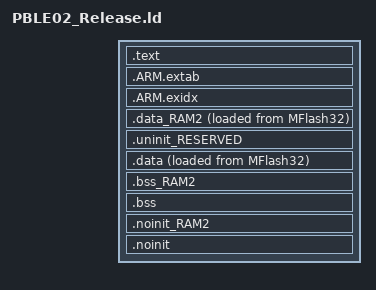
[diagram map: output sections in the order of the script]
/*
 * GENERATED FILE - DO NOT EDIT
 * Copyright 2008-2013 Code Red Technologies Ltd,
 * Copyright 2013-2025 NXP
 * SPDX-License-Identifier: BSD-3-Clause
 * Generated linker script file for LPC11U14/201
 * Created from linkscript.ldt by FMCreateLinkLibraries
 * Using Freemarker v2.3.30
 * MCUXpresso IDE v24.12 [Build 148] [2025-01-10] on 15 de jul. de 2025 22:58:17
 */

INCLUDE "PBLE02_Release_library.ld"
INCLUDE "PBLE02_Release_memory.ld"

ENTRY(ResetISR)

SECTIONS
{
     /* MAIN TEXT SECTION */
    .text : ALIGN(4)
    {
        FILL(0xff)
        __vectors_start__ = ABSOLUTE(.) ;
        KEEP(*(.isr_vector))
        /* Global Section Table */
        . = ALIGN(4) ;
        __section_table_start = .;
        __data_section_table = .;
        LONG(LOADADDR(.data));
        LONG(    ADDR(.data));
        LONG(  SIZEOF(.data));
        LONG(LOADADDR(.data_RAM2));
        LONG(    ADDR(.data_RAM2));
        LONG(  SIZEOF(.data_RAM2));
        __data_section_table_end = .;
        __bss_section_table = .;
        LONG(    ADDR(.bss));
        LONG(  SIZEOF(.bss));
        LONG(    ADDR(.bss_RAM2));
        LONG(  SIZEOF(.bss_RAM2));
        __bss_section_table_end = .;
        __section_table_end = . ;
        /* End of Global Section Table */

        *(.after_vectors*)

       *(.text*)
       *(.rodata .rodata.* .constdata .constdata.*)
       . = ALIGN(4);
    } > MFlash32
    /*
     * for exception handling/unwind - some Newlib functions (in common
     * with C++ and STDC++) use this.
     */
    .ARM.extab : ALIGN(4)
    {
        *(.ARM.extab* .gnu.linkonce.armextab.*)
    } > MFlash32

    .ARM.exidx : ALIGN(4)
    {
        __exidx_start = .;
        *(.ARM.exidx* .gnu.linkonce.armexidx.*)
        __exidx_end = .;
    } > MFlash32
 
    _etext = .;
        
    /* DATA section for RamUsb2 */

    .data_RAM2 : ALIGN(4)
    {
        FILL(0xff)
        PROVIDE(__start_data_RAM2 = .) ;
        PROVIDE(__start_data_RamUsb2 = .) ;
        *(.ramfunc.$RAM2)
        *(.ramfunc.$RamUsb2)
        *(.data.$RAM2)
        *(.data.$RamUsb2)
        *(.data.$RAM2.*)
        *(.data.$RamUsb2.*)
        . = ALIGN(4) ;
        PROVIDE(__end_data_RAM2 = .) ;
        PROVIDE(__end_data_RamUsb2 = .) ;
     } > RamUsb2 AT>MFlash32

    /* MAIN DATA SECTION */
    .uninit_RESERVED (NOLOAD) : ALIGN(4)
    {
        _start_uninit_RESERVED = .;
        KEEP(*(.bss.$RESERVED*))
       . = ALIGN(4) ;
        _end_uninit_RESERVED = .;
    } > RamLoc4 AT> RamLoc4

    /* Main DATA section (RamLoc4) */
    .data : ALIGN(4)
    {
       FILL(0xff)
       _data = . ;
       PROVIDE(__start_data_RAM = .) ;
       PROVIDE(__start_data_RamLoc4 = .) ;
       *(vtable)
       *(.ramfunc*)
       KEEP(*(CodeQuickAccess))
       KEEP(*(DataQuickAccess))
       *(RamFunction)
       *(.data*)
       . = ALIGN(4) ;
       _edata = . ;
       PROVIDE(__end_data_RAM = .) ;
       PROVIDE(__end_data_RamLoc4 = .) ;
    } > RamLoc4 AT>MFlash32

    /* BSS section for RamUsb2 */
    .bss_RAM2 (NOLOAD) : ALIGN(4)
    {
       PROVIDE(__start_bss_RAM2 = .) ;
       PROVIDE(__start_bss_RamUsb2 = .) ;
       *(.bss.$RAM2)
       *(.bss.$RamUsb2)
       *(.bss.$RAM2.*)
       *(.bss.$RamUsb2.*)
       . = ALIGN (. != 0 ? 4 : 1) ; /* avoid empty segment */
       PROVIDE(__end_bss_RAM2 = .) ;
       PROVIDE(__end_bss_RamUsb2 = .) ;
    } > RamUsb2 AT> RamUsb2

    /* MAIN BSS SECTION */
    .bss (NOLOAD) : ALIGN(4)
    {
        _bss = .;
        PROVIDE(__start_bss_RAM = .) ;
        PROVIDE(__start_bss_RamLoc4 = .) ;
        *(.bss*)
        *(COMMON)
        . = ALIGN(4) ;
        _ebss = .;
        PROVIDE(__end_bss_RAM = .) ;
        PROVIDE(__end_bss_RamLoc4 = .) ;
        PROVIDE(end = .);
    } > RamLoc4 AT> RamLoc4

    /* NOINIT section for RamUsb2 */
    .noinit_RAM2 (NOLOAD) : ALIGN(4)
    {
       PROVIDE(__start_noinit_RAM2 = .) ;
       PROVIDE(__start_noinit_RamUsb2 = .) ;
       *(.noinit.$RAM2)
       *(.noinit.$RamUsb2)
       *(.noinit.$RAM2.*)
       *(.noinit.$RamUsb2.*)
       . = ALIGN(4) ;
       PROVIDE(__end_noinit_RAM2 = .) ;
       PROVIDE(__end_noinit_RamUsb2 = .) ;
    } > RamUsb2 AT> RamUsb2

    /* DEFAULT NOINIT SECTION */
    .noinit (NOLOAD): ALIGN(4)
    {
        _noinit = .;
        PROVIDE(__start_noinit_RAM = .) ;
        PROVIDE(__start_noinit_RamLoc4 = .) ;
        *(.noinit*)
         . = ALIGN(4) ;
        _end_noinit = .;
       PROVIDE(__end_noinit_RAM = .) ;
       PROVIDE(__end_noinit_RamLoc4 = .) ;        
    } > RamLoc4 AT> RamLoc4

    PROVIDE(_pvHeapStart = DEFINED(__user_heap_base) ? __user_heap_base : .);

    PROVIDE(_vStackTop = DEFINED(__user_stack_top) ? __user_stack_top : __top_RamLoc4 - 0);

    /* ## Create checksum value (used in startup) ## */
    PROVIDE(__valid_user_code_checksum = 0 - 
                                         (_vStackTop 
                                         + (ResetISR + 1) 
                                         + (( DEFINED(NMI_Handler) ? NMI_Handler : M0_NMI_Handler ) + 1) 
                                         + (( DEFINED(HardFault_Handler) ? HardFault_Handler : M0_HardFault_Handler ) + 1) 
                                         )
           );

    /* Provide basic symbols giving location and size of main text
     * block, including initial values of RW data sections. Note that
     * these will need extending to give a complete picture with
     * complex images (e.g multiple Flash banks).
     */
    _image_start = LOADADDR(.text);
    _image_end = LOADADDR(.data) + SIZEOF(.data);
    _image_size = _image_end - _image_start;
}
